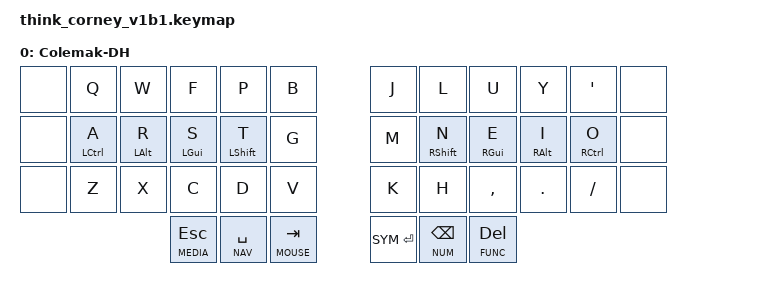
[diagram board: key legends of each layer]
#include <behaviors.dtsi>
#include <dt-bindings/zmk/keys.h>

#define ALPHA 0
#define NAV 1
#define NUM 2
#define SYMBOL 3
#define MEDIA 4
#define FUNC 5

/ {

  keymap {
    compatible = "zmk,keymap";

    Alpha_layer {
      display-name = "Colemak-DH";
      bindings = <
// ╭──────────────────┬──────────────────┬──────────────────┬──────────────────┬──────────────────┬──────────────────╮    ╭──────────────────┬──────────────────┬──────────────────┬──────────────────┬──────────────────┬──────────────────╮
     &none              &kp Q              &kp W              &kp F              &kp P              &kp B                   &kp J              &kp L              &kp U              &kp Y              &kp SINGLE_QUOTE   &none
// ├──────────────────┼──────────────────┼──────────────────┼──────────────────┼──────────────────┼──────────────────┤    ├──────────────────┼──────────────────┼──────────────────┼──────────────────┼──────────────────┼──────────────────┤
     &none              &mt LCTRL A        &mt LALT R         &mt LGUI S         &mt LSHFT T        &kp G                   &kp M              &mt RSHFT N        &mt RGUI E         &mt RALT I         &mt RCTRL O        &none
// ├──────────────────┼──────────────────┼──────────────────┼──────────────────┼──────────────────┼──────────────────┤    ├──────────────────┼──────────────────┼──────────────────┼──────────────────┼──────────────────┼──────────────────┤
     &none              &kp Z              &kp X              &kp C              &kp D              &kp V                   &kp K              &kp H              &kp COMMA          &kp PERIOD         &kp SLASH          &none
// ╰──────────────────┴──────────────────┴──────────────────┴──────────────────┼──────────────────┼──────────────────┤    ├──────────────────┼──────────────────┼──────────────────┼──────────────────┼──────────────────┼──────────────────╯
                                                              &lt MEDIA ESC      &lt NAV SPACE      &lt MOUSE TAB           & SYM RET          &lt NUM BSPC       &lt FUNC DEL
//                                                          ╰──────────────────┴──────────────────┴──────────────────╯    ╰──────────────────┴──────────────────┴──────────────────╯

      >;
    };
  };
};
